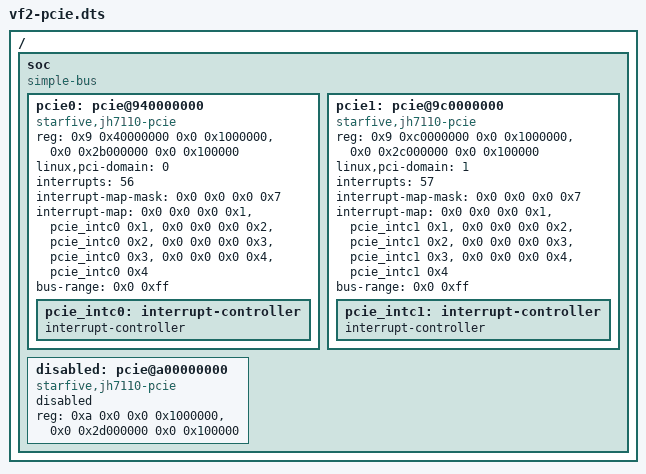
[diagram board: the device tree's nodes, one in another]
/dts-v1/;

/*
 * The VisionFive 2's two PCIe root complexes, as the JH7110 device tree
 * describes them (cfg, apb, ranges, interrupts, interrupt-map to the root
 * complex's own interrupt controller), for the host check of pci-plda.c.
 */
/ {
	#address-cells = <2>;
	#size-cells = <2>;

	soc {
		#address-cells = <2>;
		#size-cells = <2>;
		compatible = "simple-bus";
		ranges;

		pcie0: pcie@940000000 {
			compatible = "starfive,jh7110-pcie";
			reg = <0x9 0x40000000 0x0 0x1000000>,
			      <0x0 0x2b000000 0x0 0x100000>;
			reg-names = "cfg", "apb";
			linux,pci-domain = <0>;
			#address-cells = <3>;
			#size-cells = <2>;
			#interrupt-cells = <1>;
			ranges = <0x82000000  0x0 0x30000000  0x0 0x30000000 0x0 0x08000000>,
				 <0xc3000000  0x9 0x00000000  0x9 0x00000000 0x0 0x40000000>;
			interrupts = <56>;
			interrupt-map-mask = <0x0 0x0 0x0 0x7>;
			interrupt-map = <0x0 0x0 0x0 0x1 &pcie_intc0 0x1>,
					<0x0 0x0 0x0 0x2 &pcie_intc0 0x2>,
					<0x0 0x0 0x0 0x3 &pcie_intc0 0x3>,
					<0x0 0x0 0x0 0x4 &pcie_intc0 0x4>;
			device_type = "pci";
			bus-range = <0x0 0xff>;

			pcie_intc0: interrupt-controller {
				#address-cells = <0>;
				#interrupt-cells = <1>;
				interrupt-controller;
			};
		};

		pcie1: pcie@9c0000000 {
			compatible = "starfive,jh7110-pcie";
			reg = <0x9 0xc0000000 0x0 0x1000000>,
			      <0x0 0x2c000000 0x0 0x100000>;
			reg-names = "cfg", "apb";
			linux,pci-domain = <1>;
			#address-cells = <3>;
			#size-cells = <2>;
			#interrupt-cells = <1>;
			ranges = <0x82000000  0x0 0x38000000  0x0 0x38000000 0x0 0x08000000>,
				 <0xc3000000  0x9 0x80000000  0x9 0x80000000 0x0 0x40000000>;
			interrupts = <57>;
			interrupt-map-mask = <0x0 0x0 0x0 0x7>;
			interrupt-map = <0x0 0x0 0x0 0x1 &pcie_intc1 0x1>,
					<0x0 0x0 0x0 0x2 &pcie_intc1 0x2>,
					<0x0 0x0 0x0 0x3 &pcie_intc1 0x3>,
					<0x0 0x0 0x0 0x4 &pcie_intc1 0x4>;
			device_type = "pci";
			bus-range = <0x0 0xff>;

			pcie_intc1: interrupt-controller {
				#address-cells = <0>;
				#interrupt-cells = <1>;
				interrupt-controller;
			};
		};

		disabled: pcie@a00000000 {
			compatible = "starfive,jh7110-pcie";
			reg = <0xa 0x0 0x0 0x1000000>, <0x0 0x2d000000 0x0 0x100000>;
			status = "disabled";
		};
	};
};
